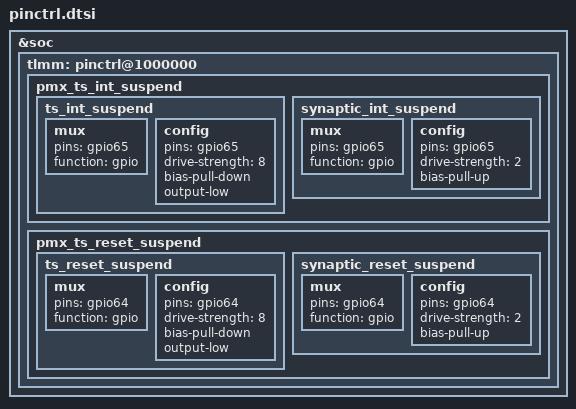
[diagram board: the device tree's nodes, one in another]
&soc {
	tlmm: pinctrl@1000000 {
        pmx_ts_int_suspend {
			ts_int_suspend: ts_int_suspend {
				mux {
					pins = "gpio65";
					function = "gpio";
				};

				config {
					pins = "gpio65";
					drive-strength = <8>;
					bias-pull-down;
					output-low;
				};
			};
			synaptic_int_suspend: synaptic_int_suspend {
				mux {
					pins = "gpio65";
					function = "gpio";
				};
				config {
					pins = "gpio65";
					drive-strength = <2>;
					bias-pull-up;
				};
			};
		};

		pmx_ts_reset_suspend {
			ts_reset_suspend: ts_reset_suspend {
				mux {
					pins = "gpio64";
					function = "gpio";
				};

				config {
					pins = "gpio64";
					drive-strength = <8>;
					bias-pull-down;
					 output-low;
				};
			};
			synaptic_reset_suspend: synaptic_reset_suspend {
				mux {
					pins = "gpio64";
					function = "gpio";
				};
				config {
					pins = "gpio64";
					drive-strength = <2>;
					bias-pull-up;
				};
			};
		};
    };
};
            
